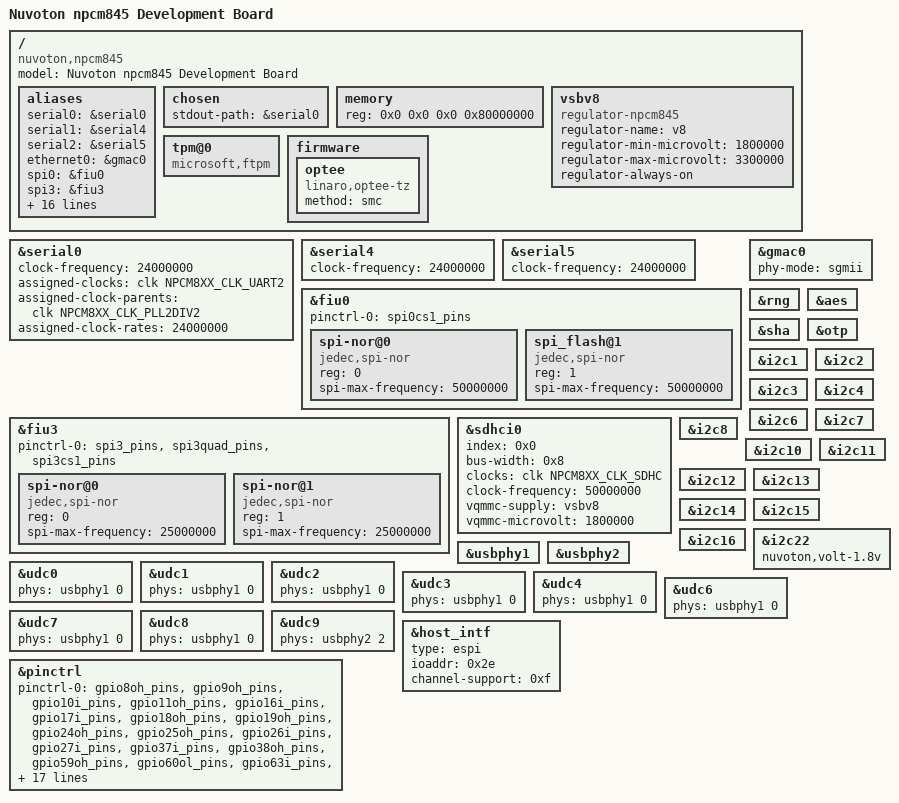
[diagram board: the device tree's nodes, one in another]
// SPDX-License-Identifier: GPL-2.0
/dts-v1/;

/* TCG2 Logs */
/memreserve/ 0x35F00000 0x00010000;

#include "nuvoton-npcm845.dtsi"
#include "nuvoton-npcm845-scm-pincfg.dtsi"

/ {
	model = "Nuvoton npcm845 Development Board";
	compatible = "nuvoton,npcm845";

	aliases {
		serial0 = &serial0;
		serial1 = &serial4;
		serial2 = &serial5;
		ethernet0 = &gmac0;
		spi0 = &fiu0;
		spi3 = &fiu3;
		usb0 = &udc0;
		i2c1 = &i2c1;
		i2c2 = &i2c2;
		i2c3 = &i2c3;
		i2c4 = &i2c4;
		i2c6 = &i2c6;
		i2c7 = &i2c7;
		i2c8 = &i2c8;
		i2c10 = &i2c10;
		i2c11 = &i2c11;
		i2c12 = &i2c12;
		i2c13 = &i2c13;
		i2c14 = &i2c14;
		i2c15 = &i2c15;
		i2c16 = &i2c16;
		i2c22 = &i2c22;
	};

	chosen {
		stdout-path = &serial0;
	};

	memory {
		reg = <0x0 0x0 0x0 0x80000000>;
	};

	vsbv8: vsbv8 {
		compatible = "regulator-npcm845";
		regulator-name = "v8";
		regulator-min-microvolt = <1800000>;
		regulator-max-microvolt = <3300000>;
		regulator-always-on;
	};

	tpm@0 {
		compatible = "microsoft,ftpm";
	};

	firmware {
		optee {
			 compatible = "linaro,optee-tz";
			 method = "smc";
		};
	};
};

&serial0 {
	status = "okay";
	clock-frequency = <24000000>;
	assigned-clocks = <&clk NPCM8XX_CLK_UART2>;
	assigned-clock-parents = <&clk NPCM8XX_CLK_PLL2DIV2>;
	assigned-clock-rates = <24000000>;
};

&serial4 {
	status = "okay";
	clock-frequency = <24000000>;
};

&serial5 {
	status = "okay";
	clock-frequency = <24000000>;
};

&fiu0 {
	status = "okay";
	pinctrl-names = "default";
	pinctrl-0 = <&spi0cs1_pins>;
	spi-nor@0 {
		compatible = "jedec,spi-nor";
		reg = <0>;
		spi-max-frequency = <50000000>;
	};
	spi_flash@1 {
		compatible = "jedec,spi-nor";
		reg = <1>;
		spi-max-frequency = <50000000>;
	};
};

&fiu3 {
	pinctrl-0 = <&spi3_pins>, <&spi3quad_pins>, <&spi3cs1_pins>;
	status = "okay";
	spi-nor@0 {
		compatible = "jedec,spi-nor";
		reg = <0>;
		spi-max-frequency = <25000000>;
	};
	spi-nor@1 {
		compatible = "jedec,spi-nor";
		reg = <1>;
		spi-max-frequency = <25000000>;
	};
};

&gmac0 {
	phy-mode = "sgmii";
	status = "okay";
};

&sdhci0 {
	index = <0x0>;
	bus-width = <0x8>;
	clocks = <&clk NPCM8XX_CLK_SDHC>;
	clock-frequency = <50000000>;
	vqmmc-supply = <&vsbv8>;
	vqmmc-microvolt = <1800000>;
	status = "okay";
};

&rng {
	status = "okay";
};

&aes {
	status = "okay";
};

&sha {
	status = "okay";
};

&otp {
	status = "okay";
};

&i2c1 {
	status = "okay";
};

&i2c2 {
	status = "okay";
};

&i2c3 {
	status = "okay";
};

&i2c4 {
	status = "okay";
};

&i2c6 {
	status = "okay";
};

&i2c7 {
	status = "okay";
};

&i2c8 {
	status = "okay";
};

&i2c10 {
	status = "okay";
};

&i2c11 {
	status = "okay";
};

&i2c12 {
	status = "okay";
};

&i2c13 {
	status = "okay";
};

&i2c14 {
	status = "okay";
};

&i2c15 {
	status = "okay";
};

&i2c16 {
	status = "okay";
};

&i2c22 {
	status = "okay";
	nuvoton,volt-1.8v;
};

&usbphy1 {
	status = "okay";
};

&usbphy2 {
	status = "okay";
};

&udc0 {
	status = "okay";
	phys = <&usbphy1 0>;
};

&udc1 {
	status = "okay";
	phys = <&usbphy1 0>;
};

&udc2 {
	status = "okay";
	phys = <&usbphy1 0>;
};

&udc3 {
	status = "okay";
	phys = <&usbphy1 0>;
};

&udc4 {
	status = "okay";
	phys = <&usbphy1 0>;
};

&udc6 {
	status = "okay";
	phys = <&usbphy1 0>;
};

&udc7 {
	status = "okay";
	phys = <&usbphy1 0>;
};

&udc8 {
	status = "okay";
	phys = <&usbphy1 0>;
};

&udc9 {
	status = "okay";
	phys = <&usbphy2 2>;
};

&host_intf {
	type = "espi";
	ioaddr = <0x2e>;
	channel-support = <0xf>;
};

&pinctrl {
        pinctrl-names = "default";
        pinctrl-0 = <
			&gpio8oh_pins
			&gpio9oh_pins
			&gpio10i_pins
			&gpio11oh_pins
			&gpio16i_pins
			&gpio17i_pins
			&gpio18oh_pins
			&gpio19oh_pins
			&gpio24oh_pins
			&gpio25oh_pins
			&gpio26i_pins
			&gpio27i_pins
			&gpio37i_pins
			&gpio38oh_pins
			&gpio59oh_pins
			&gpio60ol_pins
			&gpio63i_pins
			&gpio64i_pins
			&gpio65i_pins
			&gpio66i_pins
			&gpio67i_pins
			&gpio68i_pins
			&gpio69i_pins
			&gpio70i_pins
			&gpio71ol_pins
			&gpio72i_pins
			&gpio73oh_pins
			&gpio74i_pins
			&gpio75oh_pins
			&gpio76i_pins
			&gpio77oh_pins
			&gpio78i_pins
			&gpio82i_pins
			&gpio83oh_pins
			&gpio93i_pins
			&gpio94i_pins
			&gpio96i_pins
			&gpio97oh_pins
			&gpio98i_pins
			&gpio99ol_pins
			&gpio100ol_pins
			&gpio101i_pins
			&gpio114i_pins
			&gpio115oh_pins
			&gpio123oh_pins
			&gpio124i_pins
			&gpio125i_pins
			&gpio127i_pins
			&gpio141i_pins
			&gpio142oh_pins
			&gpio143i_pins
			&gpio145ol_pins
			&gpio146ol_pins
			&gpio147i_pins
			&gpio194i_pins
			&gpio195i_pins
			&gpio196i_pins
			&gpio197i_pins
			&gpio198i_pins
			&gpio199i_pins
			&gpio202i_pins
        >;
};
